# sysctl register map
Vendor: Texas Instruments
Peripheral module from a debugger description file (folder tm4e123gh6zrb).
Registers are 32-bit, read-write, no defined reset value unless marked. A register's access mark holds for its fields unless they carry their own. Offsets are as the file gives them; lines under a group give offsets from that group; [hi:lo] are bit positions; {n}, {i} and the like mark numbered series; 'fields as' and 'values as' point back to an identical list; <NAME> marks a mode.

## SYSCTL — System Control register addresses
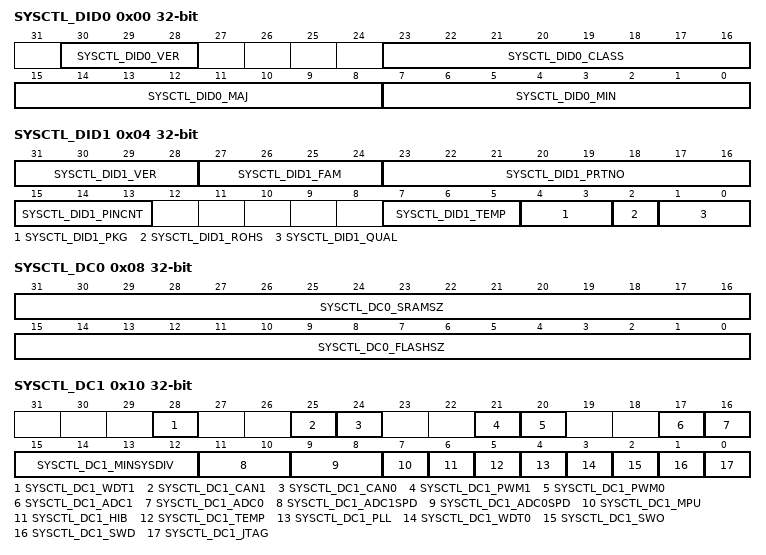
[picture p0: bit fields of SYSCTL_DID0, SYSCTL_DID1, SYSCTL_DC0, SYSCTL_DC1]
0x00 SYSCTL_DID0 ro — Device Identification 0
  [30:28] SYSCTL_DID0_VER — DID0 Version
    1=Second version of the DID0 register format
  [23:16] SYSCTL_DID0_CLASS — Device Class
    5=SYSCTL_DID0_CLASS_TM4C123 (Tiva TM4C123x and TM4E123x microcontrollers)
  [15:8] SYSCTL_DID0_MAJ — Major Revision
    0=SYSCTL_DID0_MAJ_REVA (Revision A (initial device)); 1=SYSCTL_DID0_MAJ_REVB (Revision B (first base layer revision)); 2=SYSCTL_DID0_MAJ_REVC (Revision C (second base layer revision))
  [7:0] SYSCTL_DID0_MIN — Minor Revision
    0=Initial device, or a major revision update; 1=First metal layer change; 2=Second metal layer change
0x04 SYSCTL_DID1 ro — Device Identification 1
  [31:28] SYSCTL_DID1_VER — DID1 Version
  [27:24] SYSCTL_DID1_FAM — Family
  [23:16] SYSCTL_DID1_PRTNO — Part Number
  [15:13] SYSCTL_DID1_PINCNT — Package Pin Count
    2=100-pin LQFP package; 3=64-pin LQFP package; 4=144-pin LQFP package; 5=157-pin BGA package; 6=128-pin TQFP package
  [7:5] SYSCTL_DID1_TEMP — Temperature Range
    1=SYSCTL_DID1_TEMP_I (Industrial temperature range); 2=SYSCTL_DID1_TEMP_E (Extended temperature range); 3=SYSCTL_DID1_TEMP_IE (Available in both industrial temperature range (-40C to 85C) and extended temperature range (-40C to 105C) devices. See)
  [4:3] SYSCTL_DID1_PKG — Package Type
    1=SYSCTL_DID1_PKG_QFP (QFP package); 2=SYSCTL_DID1_PKG_BGA (BGA package)
  [2] SYSCTL_DID1_ROHS — RoHS-Compliance
  [1:0] SYSCTL_DID1_QUAL — Qualification Status
    0=SYSCTL_DID1_QUAL_ES (Engineering Sample (unqualified)); 1=SYSCTL_DID1_QUAL_PP (Pilot Production (unqualified)); 2=SYSCTL_DID1_QUAL_FQ (Fully Qualified)
0x08 SYSCTL_DC0 ro — Device Capabilities 0
  [31:16] SYSCTL_DC0_SRAMSZ — SRAM Size
    7=SYSCTL_DC0_SRAMSZ_2KB (2 KB of SRAM); 15=SYSCTL_DC0_SRAMSZ_4KB (4 KB of SRAM); 23=SYSCTL_DC0_SRAMSZ_6KB (6 KB of SRAM); 31=SYSCTL_DC0_SRAMSZ_8KB (8 KB of SRAM); 47=SYSCTL_DC0_SRAMSZ_12KB (12 KB of SRAM); 63=SYSCTL_DC0_SRAMSZ_16KB (16 KB of SRAM); 79=SYSCTL_DC0_SRAMSZ_20KB (20 KB of SRAM); 95=SYSCTL_DC0_SRAMSZ_24KB (24 KB of SRAM); 127=SYSCTL_DC0_SRAMSZ_32KB (32 KB of SRAM)
  [15:0] SYSCTL_DC0_FLASHSZ — Flash Size
    3=SYSCTL_DC0_FLASHSZ_8KB (8 KB of Flash); 7=SYSCTL_DC0_FLASHSZ_16KB (16 KB of Flash); 15=SYSCTL_DC0_FLASHSZ_32KB (32 KB of Flash); 31=SYSCTL_DC0_FLASHSZ_64KB (64 KB of Flash); 47=SYSCTL_DC0_FLASHSZ_96KB (96 KB of Flash); 63=SYSCTL_DC0_FLASHSZ_128K (128 KB of Flash); 95=SYSCTL_DC0_FLASHSZ_192K (192 KB of Flash); 127=SYSCTL_DC0_FLASHSZ_256K (256 KB of Flash)
0x10 SYSCTL_DC1 ro — Device Capabilities 1
  [28] SYSCTL_DC1_WDT1 — Watchdog Timer1 Present
  [25] SYSCTL_DC1_CAN1 — CAN Module 1 Present
  [24] SYSCTL_DC1_CAN0 — CAN Module 0 Present
  [21] SYSCTL_DC1_PWM1 — PWM Module 1 Present
  [20] SYSCTL_DC1_PWM0 — PWM Module 0 Present
  [17] SYSCTL_DC1_ADC1 — ADC Module 1 Present
  [16] SYSCTL_DC1_ADC0 — ADC Module 0 Present
  [15:12] SYSCTL_DC1_MINSYSDIV — System Clock Divider
    2=Specifies an 80-MHz CPU clock with a PLL divider of 2.5; 3=Specifies a 50-MHz CPU clock with a PLL divider of 4; 4=Specifies a 40-MHz CPU clock with a PLL divider of 5; 7=Specifies a 25-MHz clock with a PLL divider of 8; 9=Specifies a 20-MHz clock with a PLL divider of 10
  [11:10] SYSCTL_DC1_ADC1SPD — Max ADC1 Speed
    0=SYSCTL_DC1_ADC1SPD_125K (125K samples/second); 1=SYSCTL_DC1_ADC1SPD_250K (250K samples/second); 2=SYSCTL_DC1_ADC1SPD_500K (500K samples/second); 3=SYSCTL_DC1_ADC1SPD_1M (1M samples/second)
  [9:8] SYSCTL_DC1_ADC0SPD — Max ADC0 Speed
    0=SYSCTL_DC1_ADC0SPD_125K (125K samples/second); 1=SYSCTL_DC1_ADC0SPD_250K (250K samples/second); 2=SYSCTL_DC1_ADC0SPD_500K (500K samples/second); 3=SYSCTL_DC1_ADC0SPD_1M (1M samples/second)
  [7] SYSCTL_DC1_MPU — MPU Present
  [6] SYSCTL_DC1_HIB — Hibernation Module Present
  [5] SYSCTL_DC1_TEMP — Temp Sensor Present
  [4] SYSCTL_DC1_PLL — PLL Present
  [3] SYSCTL_DC1_WDT0 — Watchdog Timer 0 Present
  [2] SYSCTL_DC1_SWO — SWO Trace Port Present
  [1] SYSCTL_DC1_SWD — SWD Present
  [0] SYSCTL_DC1_JTAG — JTAG Present
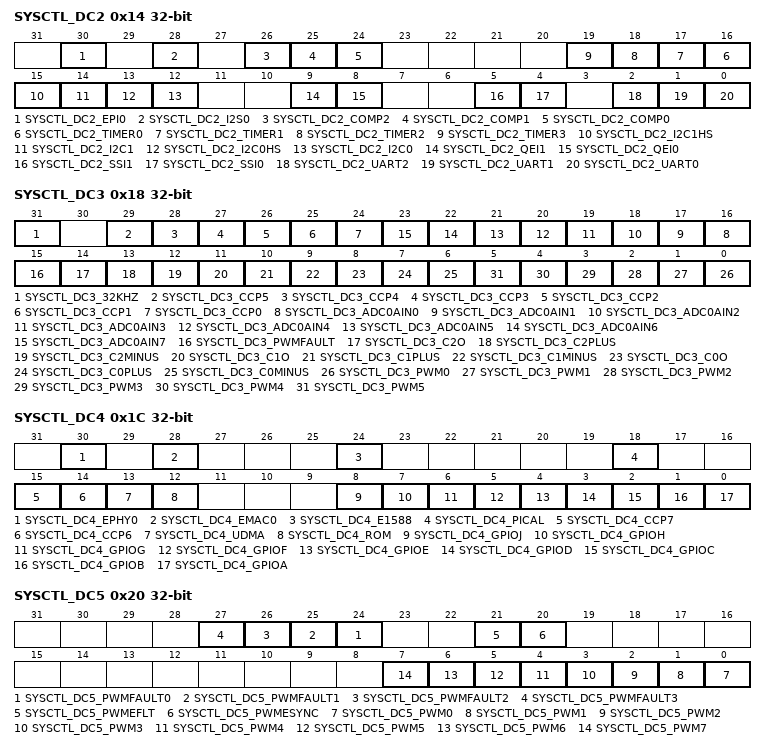
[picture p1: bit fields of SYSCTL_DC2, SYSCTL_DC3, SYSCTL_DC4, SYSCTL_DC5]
0x14 SYSCTL_DC2 ro — Device Capabilities 2
  [30] SYSCTL_DC2_EPI0 — EPI Module 0 Present
  [28] SYSCTL_DC2_I2S0 — I2S Module 0 Present
  [26] SYSCTL_DC2_COMP2 — Analog Comparator 2 Present
  [25] SYSCTL_DC2_COMP1 — Analog Comparator 1 Present
  [24] SYSCTL_DC2_COMP0 — Analog Comparator 0 Present
  [n+16] SYSCTL_DC2_TIMER{n} (n=0..3) — Timer Module {n} Present
  [15] SYSCTL_DC2_I2C1HS — I2C Module 1 Speed
  [14] SYSCTL_DC2_I2C1 — I2C Module 1 Present
  [13] SYSCTL_DC2_I2C0HS — I2C Module 0 Speed
  [12] SYSCTL_DC2_I2C0 — I2C Module 0 Present
  [9] SYSCTL_DC2_QEI1 — QEI Module 1 Present
  [8] SYSCTL_DC2_QEI0 — QEI Module 0 Present
  [5] SYSCTL_DC2_SSI1 — SSI Module 1 Present
  [4] SYSCTL_DC2_SSI0 — SSI Module 0 Present
  [2] SYSCTL_DC2_UART2 — UART Module 2 Present
  [1] SYSCTL_DC2_UART1 — UART Module 1 Present
  [0] SYSCTL_DC2_UART0 — UART Module 0 Present
0x18 SYSCTL_DC3 ro — Device Capabilities 3
  [31] SYSCTL_DC3_32KHZ — 32KHz Input Clock Available
  [29] SYSCTL_DC3_CCP5 — T2CCP1 Pin Present
  [28] SYSCTL_DC3_CCP4 — T2CCP0 Pin Present
  [27] SYSCTL_DC3_CCP3 — T1CCP1 Pin Present
  [26] SYSCTL_DC3_CCP2 — T1CCP0 Pin Present
  [25] SYSCTL_DC3_CCP1 — T0CCP1 Pin Present
  [24] SYSCTL_DC3_CCP0 — T0CCP0 Pin Present
  [n+16] SYSCTL_DC3_ADC0AIN{n} (n=0..7) — ADC Module 0 AIN{n} Pin Present
  [15] SYSCTL_DC3_PWMFAULT — PWM Fault Pin Present
  [14] SYSCTL_DC3_C2O — C2o Pin Present
  [13] SYSCTL_DC3_C2PLUS — C2+ Pin Present
  [12] SYSCTL_DC3_C2MINUS — C2- Pin Present
  [11] SYSCTL_DC3_C1O — C1o Pin Present
  [10] SYSCTL_DC3_C1PLUS — C1+ Pin Present
  [9] SYSCTL_DC3_C1MINUS — C1- Pin Present
  [8] SYSCTL_DC3_C0O — C0o Pin Present
  [7] SYSCTL_DC3_C0PLUS — C0+ Pin Present
  [6] SYSCTL_DC3_C0MINUS — C0- Pin Present
  [n] SYSCTL_DC3_PWM{n} (n=0..5) — PWM{n} Pin Present
0x1C SYSCTL_DC4 ro — Device Capabilities 4
  [30] SYSCTL_DC4_EPHY0 — Ethernet PHY Layer 0 Present
  [28] SYSCTL_DC4_EMAC0 — Ethernet MAC Layer 0 Present
  [24] SYSCTL_DC4_E1588 — 1588 Capable
  [18] SYSCTL_DC4_PICAL — PIOSC Calibrate
  [15] SYSCTL_DC4_CCP7 — T3CCP1 Pin Present
  [14] SYSCTL_DC4_CCP6 — T3CCP0 Pin Present
  [13] SYSCTL_DC4_UDMA — Micro-DMA Module Present
  [12] SYSCTL_DC4_ROM — Internal Code ROM Present
  [8] SYSCTL_DC4_GPIOJ — GPIO Port J Present
  [7] SYSCTL_DC4_GPIOH — GPIO Port H Present
  [6] SYSCTL_DC4_GPIOG — GPIO Port G Present
  [5] SYSCTL_DC4_GPIOF — GPIO Port F Present
  [4] SYSCTL_DC4_GPIOE — GPIO Port E Present
  [3] SYSCTL_DC4_GPIOD — GPIO Port D Present
  [2] SYSCTL_DC4_GPIOC — GPIO Port C Present
  [1] SYSCTL_DC4_GPIOB — GPIO Port B Present
  [0] SYSCTL_DC4_GPIOA — GPIO Port A Present
0x20 SYSCTL_DC5 ro — Device Capabilities 5
  [n+24] SYSCTL_DC5_PWMFAULT{n} (n=0..3) — PWM Fault {n} Pin Present
  [21] SYSCTL_DC5_PWMEFLT — PWM Extended Fault Active
  [20] SYSCTL_DC5_PWMESYNC — PWM Extended SYNC Active
  [n] SYSCTL_DC5_PWM{n} (n=0..7) — PWM{n} Pin Present
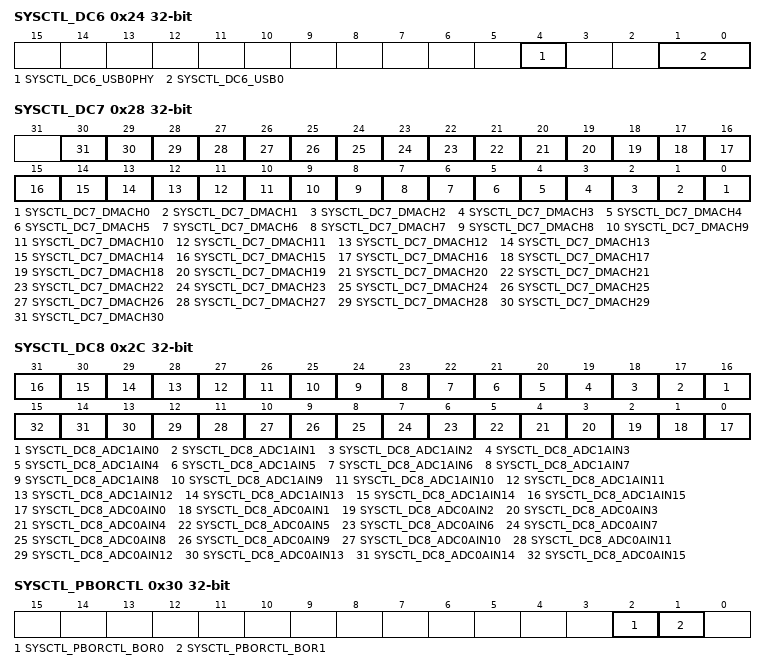
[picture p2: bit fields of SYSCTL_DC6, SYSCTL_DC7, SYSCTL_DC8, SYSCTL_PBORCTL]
0x24 SYSCTL_DC6 ro — Device Capabilities 6
  [4] SYSCTL_DC6_USB0PHY — USB Module 0 PHY Present
  [1:0] SYSCTL_DC6_USB0 — USB Module 0 Present
    1=SYSCTL_DC6_USB0_DEV (USB0 is Device Only); 2=SYSCTL_DC6_USB0_HOSTDEV (USB is Device or Host); 3=SYSCTL_DC6_USB0_OTG (USB0 is OTG)
0x28 SYSCTL_DC7 ro — Device Capabilities 7
  [n] SYSCTL_DC7_DMACH{n} (n=0..30) — DMA Channel {n}
0x2C SYSCTL_DC8 ro — Device Capabilities 8
  [n+16] SYSCTL_DC8_ADC1AIN{n} (n=0..15) — ADC Module 1 AIN{n} Pin Present
  [n] SYSCTL_DC8_ADC0AIN{n} (n=0..15) — ADC Module 0 AIN{n} Pin Present
0x30 SYSCTL_PBORCTL — Brown-Out Reset Control
  [2] SYSCTL_PBORCTL_BOR0 — VDD under BOR0 Event Action
  [1] SYSCTL_PBORCTL_BOR1 — VDD under BOR1 Event Action
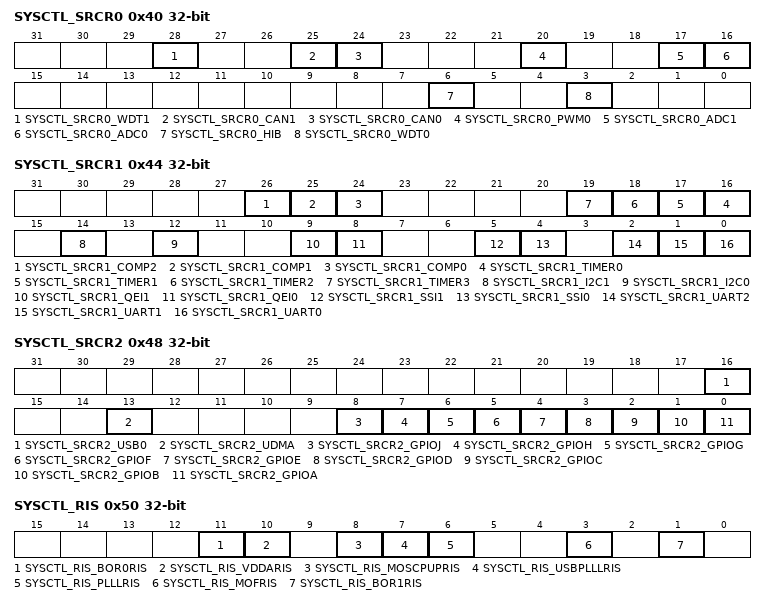
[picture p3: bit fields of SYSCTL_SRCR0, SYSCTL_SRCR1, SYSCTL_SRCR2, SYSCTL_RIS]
0x40 SYSCTL_SRCR0 ro — Software Reset Control 0
  [28] SYSCTL_SRCR0_WDT1 — WDT1 Reset Control
  [25] SYSCTL_SRCR0_CAN1 — CAN1 Reset Control
  [24] SYSCTL_SRCR0_CAN0 — CAN0 Reset Control
  [20] SYSCTL_SRCR0_PWM0 — PWM Reset Control
  [17] SYSCTL_SRCR0_ADC1 — ADC1 Reset Control
  [16] SYSCTL_SRCR0_ADC0 — ADC0 Reset Control
  [6] SYSCTL_SRCR0_HIB — HIB Reset Control
  [3] SYSCTL_SRCR0_WDT0 — WDT0 Reset Control
0x44 SYSCTL_SRCR1 ro — Software Reset Control 1
  [26] SYSCTL_SRCR1_COMP2 — Analog Comp 2 Reset Control
  [25] SYSCTL_SRCR1_COMP1 — Analog Comp 1 Reset Control
  [24] SYSCTL_SRCR1_COMP0 — Analog Comp 0 Reset Control
  [n+16] SYSCTL_SRCR1_TIMER{n} (n=0..3) — Timer {n} Reset Control
  [14] SYSCTL_SRCR1_I2C1 — I2C1 Reset Control
  [12] SYSCTL_SRCR1_I2C0 — I2C0 Reset Control
  [9] SYSCTL_SRCR1_QEI1 — QEI1 Reset Control
  [8] SYSCTL_SRCR1_QEI0 — QEI0 Reset Control
  [5] SYSCTL_SRCR1_SSI1 — SSI1 Reset Control
  [4] SYSCTL_SRCR1_SSI0 — SSI0 Reset Control
  [2] SYSCTL_SRCR1_UART2 — UART2 Reset Control
  [1] SYSCTL_SRCR1_UART1 — UART1 Reset Control
  [0] SYSCTL_SRCR1_UART0 — UART0 Reset Control
0x48 SYSCTL_SRCR2 ro — Software Reset Control 2
  [16] SYSCTL_SRCR2_USB0 — USB0 Reset Control
  [13] SYSCTL_SRCR2_UDMA — Micro-DMA Reset Control
  [8] SYSCTL_SRCR2_GPIOJ — Port J Reset Control
  [7] SYSCTL_SRCR2_GPIOH — Port H Reset Control
  [6] SYSCTL_SRCR2_GPIOG — Port G Reset Control
  [5] SYSCTL_SRCR2_GPIOF — Port F Reset Control
  [4] SYSCTL_SRCR2_GPIOE — Port E Reset Control
  [3] SYSCTL_SRCR2_GPIOD — Port D Reset Control
  [2] SYSCTL_SRCR2_GPIOC — Port C Reset Control
  [1] SYSCTL_SRCR2_GPIOB — Port B Reset Control
  [0] SYSCTL_SRCR2_GPIOA — Port A Reset Control
0x50 SYSCTL_RIS ro — Raw Interrupt Status
  [11] SYSCTL_RIS_BOR0RIS — VDD under BOR0 Raw Interrupt Status
  [10] SYSCTL_RIS_VDDARIS — VDDA Power OK Event Raw Interrupt Status
  [8] SYSCTL_RIS_MOSCPUPRIS — MOSC Power Up Raw Interrupt Status
  [7] SYSCTL_RIS_USBPLLLRIS — USB PLL Lock Raw Interrupt Status
  [6] SYSCTL_RIS_PLLLRIS — PLL Lock Raw Interrupt Status
  [3] SYSCTL_RIS_MOFRIS — Main Oscillator Failure Raw Interrupt Status
  [1] SYSCTL_RIS_BOR1RIS — VDD under BOR1 Raw Interrupt Status
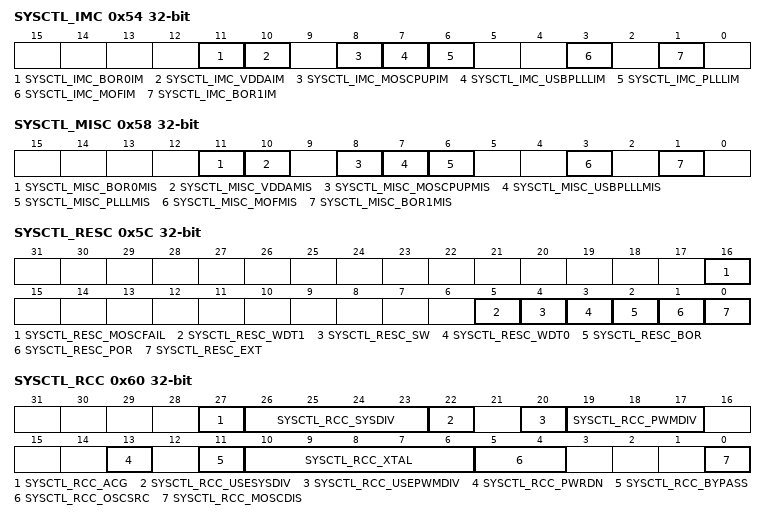
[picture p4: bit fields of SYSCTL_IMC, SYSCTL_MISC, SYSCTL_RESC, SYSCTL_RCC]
0x54 SYSCTL_IMC — Interrupt Mask Control
  [11] SYSCTL_IMC_BOR0IM — VDD under BOR0 Interrupt Mask
  [10] SYSCTL_IMC_VDDAIM — VDDA Power OK Interrupt Mask
  [8] SYSCTL_IMC_MOSCPUPIM — MOSC Power Up Interrupt Mask
  [7] SYSCTL_IMC_USBPLLLIM — USB PLL Lock Interrupt Mask
  [6] SYSCTL_IMC_PLLLIM — PLL Lock Interrupt Mask
  [3] SYSCTL_IMC_MOFIM — Main Oscillator Failure Interrupt Mask
  [1] SYSCTL_IMC_BOR1IM — VDD under BOR1 Interrupt Mask
0x58 SYSCTL_MISC — Masked Interrupt Status and Clear
  [11] SYSCTL_MISC_BOR0MIS — VDD under BOR0 Masked Interrupt Status
  [10] SYSCTL_MISC_VDDAMIS — VDDA Power OK Masked Interrupt Status
  [8] SYSCTL_MISC_MOSCPUPMIS — MOSC Power Up Masked Interrupt Status
  [7] SYSCTL_MISC_USBPLLLMIS — USB PLL Lock Masked Interrupt Status
  [6] SYSCTL_MISC_PLLLMIS — PLL Lock Masked Interrupt Status
  [3] SYSCTL_MISC_MOFMIS — Main Oscillator Failure Masked Interrupt Status
  [1] SYSCTL_MISC_BOR1MIS — VDD under BOR1 Masked Interrupt Status
0x5C SYSCTL_RESC — Reset Cause
  [16] SYSCTL_RESC_MOSCFAIL — MOSC Failure Reset
  [5] SYSCTL_RESC_WDT1 — Watchdog Timer 1 Reset
  [4] SYSCTL_RESC_SW — Software Reset
  [3] SYSCTL_RESC_WDT0 — Watchdog Timer 0 Reset
  [2] SYSCTL_RESC_BOR — Brown-Out Reset
  [1] SYSCTL_RESC_POR — Power-On Reset
  [0] SYSCTL_RESC_EXT — External Reset
0x60 SYSCTL_RCC — Run-Mode Clock Configuration
  [27] SYSCTL_RCC_ACG — Auto Clock Gating
  [26:23] SYSCTL_RCC_SYSDIV — System Clock Divisor
  [22] SYSCTL_RCC_USESYSDIV — Enable System Clock Divider
  [20] SYSCTL_RCC_USEPWMDIV — Enable PWM Clock Divisor
  [19:17] SYSCTL_RCC_PWMDIV — PWM Unit Clock Divisor
    0=PWM clock /2; 1=PWM clock /4; 2=PWM clock /8; 3=PWM clock /16; 4=PWM clock /32; 5=PWM clock /64
  [13] SYSCTL_RCC_PWRDN — PLL Power Down
  [11] SYSCTL_RCC_BYPASS — PLL Bypass
  [10:6] SYSCTL_RCC_XTAL — Crystal Value
    6=SYSCTL_RCC_XTAL_4MHZ (4 MHz); 7=SYSCTL_RCC_XTAL_4_09MHZ (4.096 MHz); 8=SYSCTL_RCC_XTAL_4_91MHZ (4.9152 MHz); 9=SYSCTL_RCC_XTAL_5MHZ (5 MHz); 10=SYSCTL_RCC_XTAL_5_12MHZ (5.12 MHz); 11=SYSCTL_RCC_XTAL_6MHZ (6 MHz); 12=SYSCTL_RCC_XTAL_6_14MHZ (6.144 MHz); 13=SYSCTL_RCC_XTAL_7_37MHZ (7.3728 MHz); 14=SYSCTL_RCC_XTAL_8MHZ (8 MHz); 15=SYSCTL_RCC_XTAL_8_19MHZ (8.192 MHz); 16=SYSCTL_RCC_XTAL_10MHZ (10 MHz); 17=SYSCTL_RCC_XTAL_12MHZ (12 MHz); 18=SYSCTL_RCC_XTAL_12_2MHZ (12.288 MHz); 19=SYSCTL_RCC_XTAL_13_5MHZ (13.56 MHz); 20=SYSCTL_RCC_XTAL_14_3MHZ (14.31818 MHz); 21=SYSCTL_RCC_XTAL_16MHZ (16 MHz); 22=SYSCTL_RCC_XTAL_16_3MHZ (16.384 MHz); 23=SYSCTL_RCC_XTAL_18MHZ (18.0 MHz (USB)); 24=SYSCTL_RCC_XTAL_20MHZ (20.0 MHz (USB)); 25=SYSCTL_RCC_XTAL_24MHZ (24.0 MHz (USB)); 26=SYSCTL_RCC_XTAL_25MHZ (25.0 MHz (USB))
  [5:4] SYSCTL_RCC_OSCSRC — Oscillator Source
    0=SYSCTL_RCC_OSCSRC_MAIN (MOSC); 1=SYSCTL_RCC_OSCSRC_INT (IOSC); 2=SYSCTL_RCC_OSCSRC_INT4 (IOSC/4); 3=LFIOSC
  [0] SYSCTL_RCC_MOSCDIS — Main Oscillator Disable
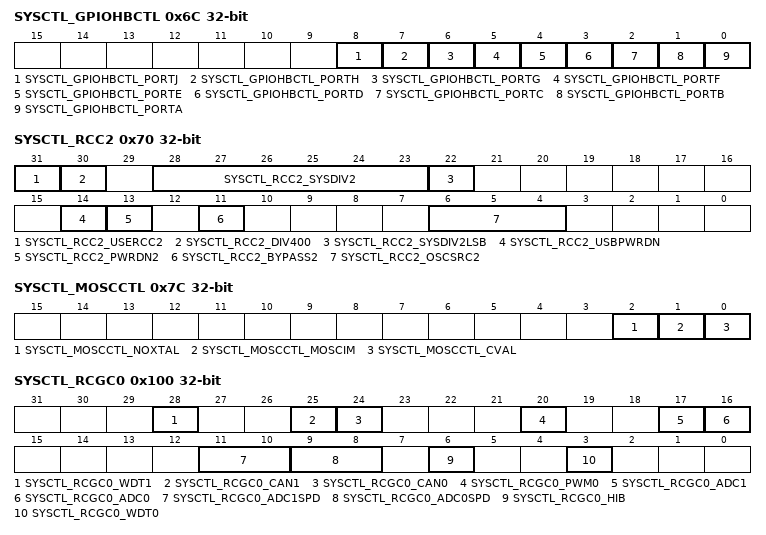
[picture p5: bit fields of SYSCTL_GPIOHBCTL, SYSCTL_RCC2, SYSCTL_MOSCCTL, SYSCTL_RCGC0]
0x6C SYSCTL_GPIOHBCTL — GPIO High-Performance Bus Control
  [8] SYSCTL_GPIOHBCTL_PORTJ — Port J Advanced High-Performance Bus
  [7] SYSCTL_GPIOHBCTL_PORTH — Port H Advanced High-Performance Bus
  [6] SYSCTL_GPIOHBCTL_PORTG — Port G Advanced High-Performance Bus
  [5] SYSCTL_GPIOHBCTL_PORTF — Port F Advanced High-Performance Bus
  [4] SYSCTL_GPIOHBCTL_PORTE — Port E Advanced High-Performance Bus
  [3] SYSCTL_GPIOHBCTL_PORTD — Port D Advanced High-Performance Bus
  [2] SYSCTL_GPIOHBCTL_PORTC — Port C Advanced High-Performance Bus
  [1] SYSCTL_GPIOHBCTL_PORTB — Port B Advanced High-Performance Bus
  [0] SYSCTL_GPIOHBCTL_PORTA — Port A Advanced High-Performance Bus
0x70 SYSCTL_RCC2 — Run-Mode Clock Configuration 2
  [31] SYSCTL_RCC2_USERCC2 — Use RCC2
  [30] SYSCTL_RCC2_DIV400 — Divide PLL as 400 MHz vs. 200 MHz
  [28:23] SYSCTL_RCC2_SYSDIV2 — System Clock Divisor 2
  [22] SYSCTL_RCC2_SYSDIV2LSB — Additional LSB for SYSDIV2
  [14] SYSCTL_RCC2_USBPWRDN — Power-Down USB PLL
  [13] SYSCTL_RCC2_PWRDN2 — Power-Down PLL 2
  [11] SYSCTL_RCC2_BYPASS2 — PLL Bypass 2
  [6:4] SYSCTL_RCC2_OSCSRC2 — Oscillator Source 2
    0=SYSCTL_RCC2_OSCSRC2_MO (MOSC); 1=SYSCTL_RCC2_OSCSRC2_IO (PIOSC); 2=SYSCTL_RCC2_OSCSRC2_IO4 (PIOSC/4); 3=LFIOSC; 7=32.768 kHz
0x7C SYSCTL_MOSCCTL — Main Oscillator Control
  [2] SYSCTL_MOSCCTL_NOXTAL — No Crystal Connected
  [1] SYSCTL_MOSCCTL_MOSCIM — MOSC Failure Action
  [0] SYSCTL_MOSCCTL_CVAL — Clock Validation for MOSC
0x100 SYSCTL_RCGC0 ro — Run Mode Clock Gating Control Register 0
  [28] SYSCTL_RCGC0_WDT1 — WDT1 Clock Gating Control
  [25] SYSCTL_RCGC0_CAN1 — CAN1 Clock Gating Control
  [24] SYSCTL_RCGC0_CAN0 — CAN0 Clock Gating Control
  [20] SYSCTL_RCGC0_PWM0 — PWM Clock Gating Control
  [17] SYSCTL_RCGC0_ADC1 — ADC1 Clock Gating Control
  [16] SYSCTL_RCGC0_ADC0 — ADC0 Clock Gating Control
  [11:10] SYSCTL_RCGC0_ADC1SPD — ADC1 Sample Speed
    0=SYSCTL_RCGC0_ADC1SPD_125K (125K samples/second); 1=SYSCTL_RCGC0_ADC1SPD_250K (250K samples/second); 2=SYSCTL_RCGC0_ADC1SPD_500K (500K samples/second); 3=SYSCTL_RCGC0_ADC1SPD_1M (1M samples/second)
  [9:8] SYSCTL_RCGC0_ADC0SPD — ADC0 Sample Speed
    0=SYSCTL_RCGC0_ADC0SPD_125K (125K samples/second); 1=SYSCTL_RCGC0_ADC0SPD_250K (250K samples/second); 2=SYSCTL_RCGC0_ADC0SPD_500K (500K samples/second); 3=SYSCTL_RCGC0_ADC0SPD_1M (1M samples/second)
  [6] SYSCTL_RCGC0_HIB — HIB Clock Gating Control
  [3] SYSCTL_RCGC0_WDT0 — WDT0 Clock Gating Control
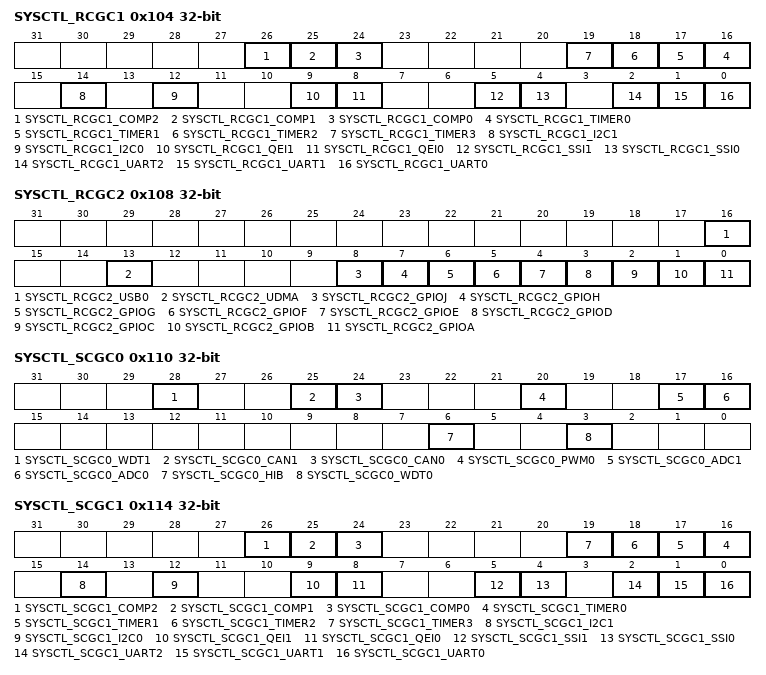
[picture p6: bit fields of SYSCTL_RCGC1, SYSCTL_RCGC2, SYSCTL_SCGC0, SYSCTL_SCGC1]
0x104 SYSCTL_RCGC1 ro — Run Mode Clock Gating Control Register 1
  [26] SYSCTL_RCGC1_COMP2 — Analog Comparator 2 Clock Gating
  [25] SYSCTL_RCGC1_COMP1 — Analog Comparator 1 Clock Gating
  [24] SYSCTL_RCGC1_COMP0 — Analog Comparator 0 Clock Gating
  [n+16] SYSCTL_RCGC1_TIMER{n} (n=0..3) — Timer {n} Clock Gating Control
  [14] SYSCTL_RCGC1_I2C1 — I2C1 Clock Gating Control
  [12] SYSCTL_RCGC1_I2C0 — I2C0 Clock Gating Control
  [9] SYSCTL_RCGC1_QEI1 — QEI1 Clock Gating Control
  [8] SYSCTL_RCGC1_QEI0 — QEI0 Clock Gating Control
  [5] SYSCTL_RCGC1_SSI1 — SSI1 Clock Gating Control
  [4] SYSCTL_RCGC1_SSI0 — SSI0 Clock Gating Control
  [2] SYSCTL_RCGC1_UART2 — UART2 Clock Gating Control
  [1] SYSCTL_RCGC1_UART1 — UART1 Clock Gating Control
  [0] SYSCTL_RCGC1_UART0 — UART0 Clock Gating Control
0x108 SYSCTL_RCGC2 ro — Run Mode Clock Gating Control Register 2
  [16] SYSCTL_RCGC2_USB0 — USB0 Clock Gating Control
  [13] SYSCTL_RCGC2_UDMA — Micro-DMA Clock Gating Control
  [8] SYSCTL_RCGC2_GPIOJ — Port J Clock Gating Control
  [7] SYSCTL_RCGC2_GPIOH — Port H Clock Gating Control
  [6] SYSCTL_RCGC2_GPIOG — Port G Clock Gating Control
  [5] SYSCTL_RCGC2_GPIOF — Port F Clock Gating Control
  [4] SYSCTL_RCGC2_GPIOE — Port E Clock Gating Control
  [3] SYSCTL_RCGC2_GPIOD — Port D Clock Gating Control
  [2] SYSCTL_RCGC2_GPIOC — Port C Clock Gating Control
  [1] SYSCTL_RCGC2_GPIOB — Port B Clock Gating Control
  [0] SYSCTL_RCGC2_GPIOA — Port A Clock Gating Control
0x110 SYSCTL_SCGC0 ro — Sleep Mode Clock Gating Control Register 0
  [28] SYSCTL_SCGC0_WDT1 — WDT1 Clock Gating Control
  [25] SYSCTL_SCGC0_CAN1 — CAN1 Clock Gating Control
  [24] SYSCTL_SCGC0_CAN0 — CAN0 Clock Gating Control
  [20] SYSCTL_SCGC0_PWM0 — PWM Clock Gating Control
  [17] SYSCTL_SCGC0_ADC1 — ADC1 Clock Gating Control
  [16] SYSCTL_SCGC0_ADC0 — ADC0 Clock Gating Control
  [6] SYSCTL_SCGC0_HIB — HIB Clock Gating Control
  [3] SYSCTL_SCGC0_WDT0 — WDT0 Clock Gating Control
0x114 SYSCTL_SCGC1 ro — Sleep Mode Clock Gating Control Register 1
  [26] SYSCTL_SCGC1_COMP2 — Analog Comparator 2 Clock Gating
  [25] SYSCTL_SCGC1_COMP1 — Analog Comparator 1 Clock Gating
  [24] SYSCTL_SCGC1_COMP0 — Analog Comparator 0 Clock Gating
  [n+16] SYSCTL_SCGC1_TIMER{n} (n=0..3) — Timer {n} Clock Gating Control
  [14] SYSCTL_SCGC1_I2C1 — I2C1 Clock Gating Control
  [12] SYSCTL_SCGC1_I2C0 — I2C0 Clock Gating Control
  [9] SYSCTL_SCGC1_QEI1 — QEI1 Clock Gating Control
  [8] SYSCTL_SCGC1_QEI0 — QEI0 Clock Gating Control
  [5] SYSCTL_SCGC1_SSI1 — SSI1 Clock Gating Control
  [4] SYSCTL_SCGC1_SSI0 — SSI0 Clock Gating Control
  [2] SYSCTL_SCGC1_UART2 — UART2 Clock Gating Control
  [1] SYSCTL_SCGC1_UART1 — UART1 Clock Gating Control
  [0] SYSCTL_SCGC1_UART0 — UART0 Clock Gating Control
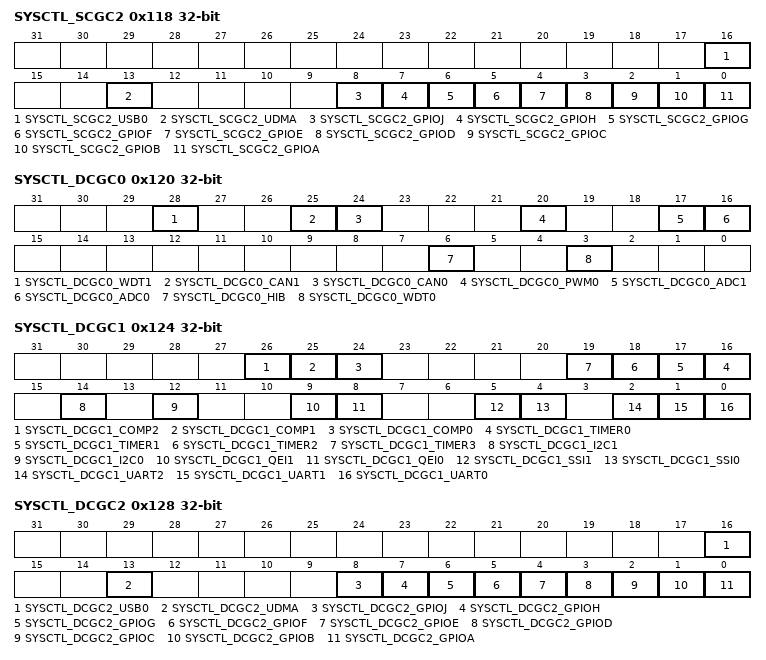
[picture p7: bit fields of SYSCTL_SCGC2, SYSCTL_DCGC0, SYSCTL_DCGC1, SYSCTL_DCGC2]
0x118 SYSCTL_SCGC2 ro — Sleep Mode Clock Gating Control Register 2
  [16] SYSCTL_SCGC2_USB0 — USB0 Clock Gating Control
  [13] SYSCTL_SCGC2_UDMA — Micro-DMA Clock Gating Control
  [8] SYSCTL_SCGC2_GPIOJ — Port J Clock Gating Control
  [7] SYSCTL_SCGC2_GPIOH — Port H Clock Gating Control
  [6] SYSCTL_SCGC2_GPIOG — Port G Clock Gating Control
  [5] SYSCTL_SCGC2_GPIOF — Port F Clock Gating Control
  [4] SYSCTL_SCGC2_GPIOE — Port E Clock Gating Control
  [3] SYSCTL_SCGC2_GPIOD — Port D Clock Gating Control
  [2] SYSCTL_SCGC2_GPIOC — Port C Clock Gating Control
  [1] SYSCTL_SCGC2_GPIOB — Port B Clock Gating Control
  [0] SYSCTL_SCGC2_GPIOA — Port A Clock Gating Control
0x120 SYSCTL_DCGC0 ro — Deep Sleep Mode Clock Gating Control Register 0
  [28] SYSCTL_DCGC0_WDT1 — WDT1 Clock Gating Control
  [25] SYSCTL_DCGC0_CAN1 — CAN1 Clock Gating Control
  [24] SYSCTL_DCGC0_CAN0 — CAN0 Clock Gating Control
  [20] SYSCTL_DCGC0_PWM0 — PWM Clock Gating Control
  [17] SYSCTL_DCGC0_ADC1 — ADC1 Clock Gating Control
  [16] SYSCTL_DCGC0_ADC0 — ADC0 Clock Gating Control
  [6] SYSCTL_DCGC0_HIB — HIB Clock Gating Control
  [3] SYSCTL_DCGC0_WDT0 — WDT0 Clock Gating Control
0x124 SYSCTL_DCGC1 ro — Deep-Sleep Mode Clock Gating Control Register 1
  [26] SYSCTL_DCGC1_COMP2 — Analog Comparator 2 Clock Gating
  [25] SYSCTL_DCGC1_COMP1 — Analog Comparator 1 Clock Gating
  [24] SYSCTL_DCGC1_COMP0 — Analog Comparator 0 Clock Gating
  [n+16] SYSCTL_DCGC1_TIMER{n} (n=0..3) — Timer {n} Clock Gating Control
  [14] SYSCTL_DCGC1_I2C1 — I2C1 Clock Gating Control
  [12] SYSCTL_DCGC1_I2C0 — I2C0 Clock Gating Control
  [9] SYSCTL_DCGC1_QEI1 — QEI1 Clock Gating Control
  [8] SYSCTL_DCGC1_QEI0 — QEI0 Clock Gating Control
  [5] SYSCTL_DCGC1_SSI1 — SSI1 Clock Gating Control
  [4] SYSCTL_DCGC1_SSI0 — SSI0 Clock Gating Control
  [2] SYSCTL_DCGC1_UART2 — UART2 Clock Gating Control
  [1] SYSCTL_DCGC1_UART1 — UART1 Clock Gating Control
  [0] SYSCTL_DCGC1_UART0 — UART0 Clock Gating Control
0x128 SYSCTL_DCGC2 ro — Deep Sleep Mode Clock Gating Control Register 2
  [16] SYSCTL_DCGC2_USB0 — USB0 Clock Gating Control
  [13] SYSCTL_DCGC2_UDMA — Micro-DMA Clock Gating Control
  [8] SYSCTL_DCGC2_GPIOJ — Port J Clock Gating Control
  [7] SYSCTL_DCGC2_GPIOH — Port H Clock Gating Control
  [6] SYSCTL_DCGC2_GPIOG — Port G Clock Gating Control
  [5] SYSCTL_DCGC2_GPIOF — Port F Clock Gating Control
  [4] SYSCTL_DCGC2_GPIOE — Port E Clock Gating Control
  [3] SYSCTL_DCGC2_GPIOD — Port D Clock Gating Control
  [2] SYSCTL_DCGC2_GPIOC — Port C Clock Gating Control
  [1] SYSCTL_DCGC2_GPIOB — Port B Clock Gating Control
  [0] SYSCTL_DCGC2_GPIOA — Port A Clock Gating Control
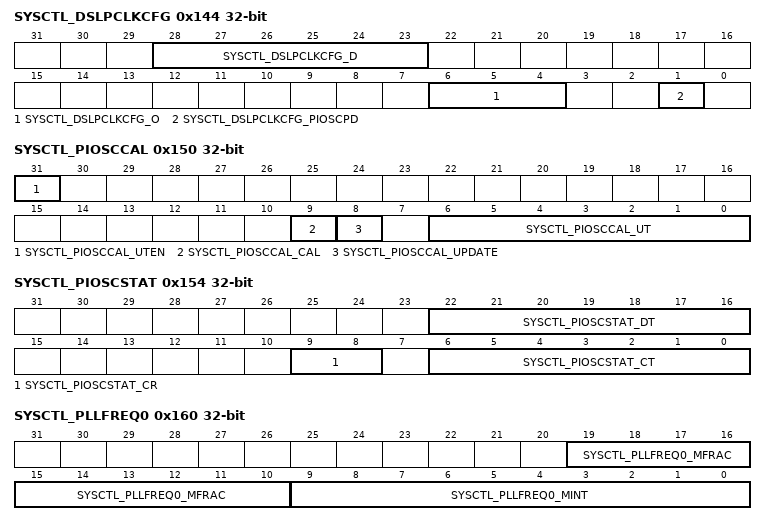
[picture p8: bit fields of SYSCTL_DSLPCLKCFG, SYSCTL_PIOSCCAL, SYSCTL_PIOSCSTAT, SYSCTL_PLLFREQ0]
0x144 SYSCTL_DSLPCLKCFG — Deep Sleep Clock Configuration
  [28:23] SYSCTL_DSLPCLKCFG_D — Divider Field Override
  [6:4] SYSCTL_DSLPCLKCFG_O — Clock Source
    0=SYSCTL_DSLPCLKCFG_O_IGN (MOSC); 1=SYSCTL_DSLPCLKCFG_O_IO (PIOSC); 3=LFIOSC; 7=32.768 kHz
  [1] SYSCTL_DSLPCLKCFG_PIOSCPD — PIOSC Power Down Request
0x14C SYSCTL_SYSPROP ro — System Properties
  [0] SYSCTL_SYSPROP_FPU — FPU Present
0x150 SYSCTL_PIOSCCAL — Precision Internal Oscillator Calibration
  [31] SYSCTL_PIOSCCAL_UTEN — Use User Trim Value
  [9] SYSCTL_PIOSCCAL_CAL — Start Calibration
  [8] SYSCTL_PIOSCCAL_UPDATE — Update Trim
  [6:0] SYSCTL_PIOSCCAL_UT — User Trim Value
0x154 SYSCTL_PIOSCSTAT ro — Precision Internal Oscillator Statistics
  [22:16] SYSCTL_PIOSCSTAT_DT — Default Trim Value
  [9:8] SYSCTL_PIOSCSTAT_CR — Calibration Result
    0=SYSCTL_PIOSCSTAT_CRNONE (Calibration has not been attempted); 1=SYSCTL_PIOSCSTAT_CRPASS (The last calibration operation completed to meet 1% accuracy); 2=SYSCTL_PIOSCSTAT_CRFAIL (The last calibration operation failed to meet 1% accuracy)
  [6:0] SYSCTL_PIOSCSTAT_CT — Calibration Trim Value
0x160 SYSCTL_PLLFREQ0 — PLL Frequency 0
  [19:10] SYSCTL_PLLFREQ0_MFRAC — PLL M Fractional Value
  [9:0] SYSCTL_PLLFREQ0_MINT — PLL M Integer Value
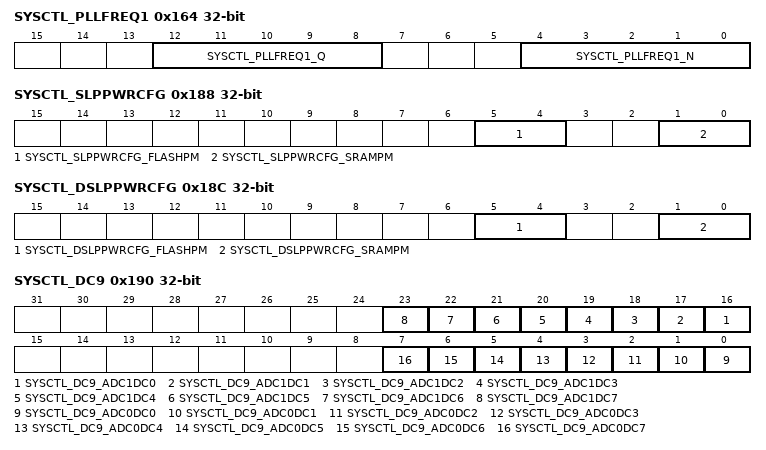
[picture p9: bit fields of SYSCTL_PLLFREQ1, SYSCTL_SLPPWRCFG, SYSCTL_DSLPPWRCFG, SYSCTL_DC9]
0x164 SYSCTL_PLLFREQ1 — PLL Frequency 1
  [12:8] SYSCTL_PLLFREQ1_Q — PLL Q Value
  [4:0] SYSCTL_PLLFREQ1_N — PLL N Value
0x168 SYSCTL_PLLSTAT ro — PLL Status
  [0] SYSCTL_PLLSTAT_LOCK — PLL Lock
0x188 SYSCTL_SLPPWRCFG — Sleep Power Configuration
  [5:4] SYSCTL_SLPPWRCFG_FLASHPM — Flash Power Modes
    0=SYSCTL_SLPPWRCFG_FLASHPM_NRM (Active Mode); 2=SYSCTL_SLPPWRCFG_FLASHPM_SLP (Low Power Mode)
  [1:0] SYSCTL_SLPPWRCFG_SRAMPM — SRAM Power Modes
    0=SYSCTL_SLPPWRCFG_SRAMPM_NRM (Active Mode); 1=SYSCTL_SLPPWRCFG_SRAMPM_SBY (Standby Mode); 3=SYSCTL_SLPPWRCFG_SRAMPM_LP (Low Power Mode)
0x18C SYSCTL_DSLPPWRCFG — Deep-Sleep Power Configuration
  [5:4] SYSCTL_DSLPPWRCFG_FLASHPM — Flash Power Modes
    0=SYSCTL_DSLPPWRCFG_FLASHPM_NRM (Active Mode); 2=SYSCTL_DSLPPWRCFG_FLASHPM_SLP (Low Power Mode)
  [1:0] SYSCTL_DSLPPWRCFG_SRAMPM — SRAM Power Modes
    0=SYSCTL_DSLPPWRCFG_SRAMPM_NRM (Active Mode); 1=SYSCTL_DSLPPWRCFG_SRAMPM_SBY (Standby Mode); 3=SYSCTL_DSLPPWRCFG_SRAMPM_LP (Low Power Mode)
0x190 SYSCTL_DC9 ro — Device Capabilities 9
  [n+16] SYSCTL_DC9_ADC1DC{n} (n=0..7) — ADC1 DC{n} Present
  [n] SYSCTL_DC9_ADC0DC{n} (n=0..7) — ADC0 DC{n} Present
0x1A0 SYSCTL_NVMSTAT ro — Non-Volatile Memory Information
  [0] SYSCTL_NVMSTAT_FWB — 32 Word Flash Write Buffer Available
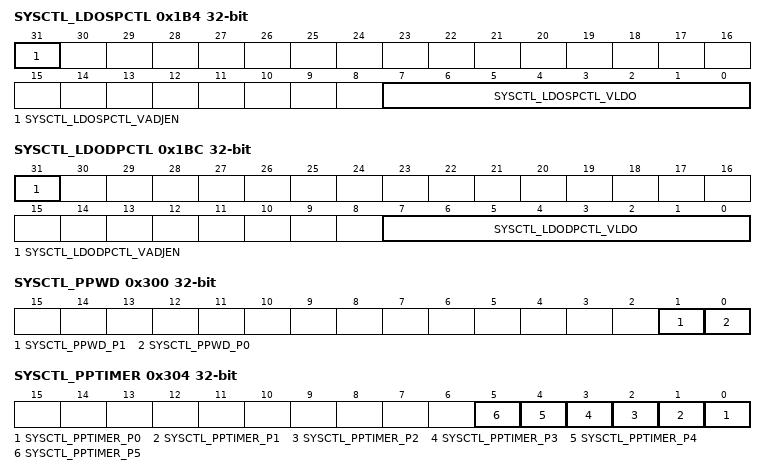
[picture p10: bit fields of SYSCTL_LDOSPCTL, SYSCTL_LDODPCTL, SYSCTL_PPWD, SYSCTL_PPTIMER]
0x1B4 SYSCTL_LDOSPCTL — LDO Sleep Power Control
  [31] SYSCTL_LDOSPCTL_VADJEN — Voltage Adjust Enable
  [7:0] SYSCTL_LDOSPCTL_VLDO — LDO Output Voltage
    18=SYSCTL_LDOSPCTL_VLDO_0_90V (0.90 V); 19=SYSCTL_LDOSPCTL_VLDO_0_95V (0.95 V); 20=SYSCTL_LDOSPCTL_VLDO_1_00V (1.00 V); 21=SYSCTL_LDOSPCTL_VLDO_1_05V (1.05 V); 22=SYSCTL_LDOSPCTL_VLDO_1_10V (1.10 V); 23=SYSCTL_LDOSPCTL_VLDO_1_15V (1.15 V); 24=SYSCTL_LDOSPCTL_VLDO_1_20V (1.20 V)
0x1BC SYSCTL_LDODPCTL — LDO Deep-Sleep Power Control
  [31] SYSCTL_LDODPCTL_VADJEN — Voltage Adjust Enable
  [7:0] SYSCTL_LDODPCTL_VLDO — LDO Output Voltage
    18=SYSCTL_LDODPCTL_VLDO_0_90V (0.90 V); 19=SYSCTL_LDODPCTL_VLDO_0_95V (0.95 V); 20=SYSCTL_LDODPCTL_VLDO_1_00V (1.00 V); 21=SYSCTL_LDODPCTL_VLDO_1_05V (1.05 V); 22=SYSCTL_LDODPCTL_VLDO_1_10V (1.10 V); 23=SYSCTL_LDODPCTL_VLDO_1_15V (1.15 V); 24=SYSCTL_LDODPCTL_VLDO_1_20V (1.20 V)
0x300 SYSCTL_PPWD ro — Watchdog Timer Peripheral Present
  [1] SYSCTL_PPWD_P1 — Watchdog Timer 1 Present
  [0] SYSCTL_PPWD_P0 — Watchdog Timer 0 Present
0x304 SYSCTL_PPTIMER ro — 16/32-Bit General-Purpose Timer Peripheral Present
  [n] SYSCTL_PPTIMER_P{n} (n=0..5) — 16/32-Bit General-Purpose Timer {n} Present
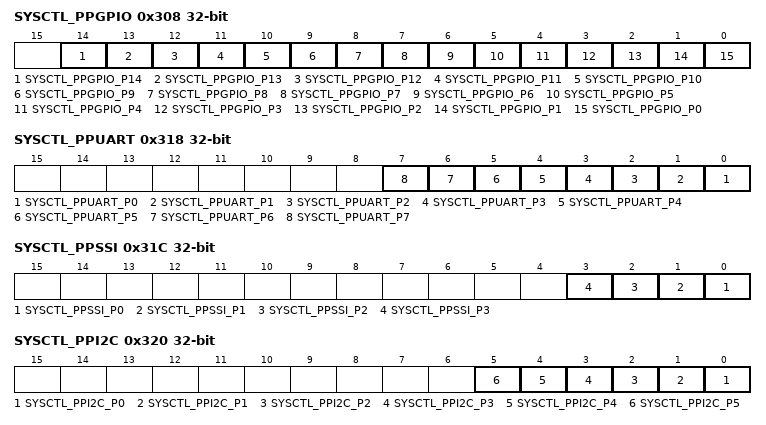
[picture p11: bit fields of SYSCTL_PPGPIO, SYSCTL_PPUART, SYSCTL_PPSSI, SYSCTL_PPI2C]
0x308 SYSCTL_PPGPIO ro — General-Purpose Input/Output Peripheral Present
  [14] SYSCTL_PPGPIO_P14 — GPIO Port Q Present
  [13] SYSCTL_PPGPIO_P13 — GPIO Port P Present
  [12] SYSCTL_PPGPIO_P12 — GPIO Port N Present
  [11] SYSCTL_PPGPIO_P11 — GPIO Port M Present
  [10] SYSCTL_PPGPIO_P10 — GPIO Port L Present
  [9] SYSCTL_PPGPIO_P9 — GPIO Port K Present
  [8] SYSCTL_PPGPIO_P8 — GPIO Port J Present
  [7] SYSCTL_PPGPIO_P7 — GPIO Port H Present
  [6] SYSCTL_PPGPIO_P6 — GPIO Port G Present
  [5] SYSCTL_PPGPIO_P5 — GPIO Port F Present
  [4] SYSCTL_PPGPIO_P4 — GPIO Port E Present
  [3] SYSCTL_PPGPIO_P3 — GPIO Port D Present
  [2] SYSCTL_PPGPIO_P2 — GPIO Port C Present
  [1] SYSCTL_PPGPIO_P1 — GPIO Port B Present
  [0] SYSCTL_PPGPIO_P0 — GPIO Port A Present
0x30C SYSCTL_PPDMA ro — Micro Direct Memory Access Peripheral Present
  [0] SYSCTL_PPDMA_P0 — uDMA Module Present
0x314 SYSCTL_PPHIB ro — Hibernation Peripheral Present
  [0] SYSCTL_PPHIB_P0 — Hibernation Module Present
0x318 SYSCTL_PPUART ro — Universal Asynchronous Receiver/Transmitter Peripheral Present
  [n] SYSCTL_PPUART_P{n} (n=0..7) — UART Module {n} Present
0x31C SYSCTL_PPSSI ro — Synchronous Serial Interface Peripheral Present
  [n] SYSCTL_PPSSI_P{n} (n=0..3) — SSI Module {n} Present
0x320 SYSCTL_PPI2C ro — Inter-Integrated Circuit Peripheral Present
  [n] SYSCTL_PPI2C_P{n} (n=0..5) — I2C Module {n} Present
0x328 SYSCTL_PPUSB ro — Universal Serial Bus Peripheral Present
  [0] SYSCTL_PPUSB_P0 — USB Module Present
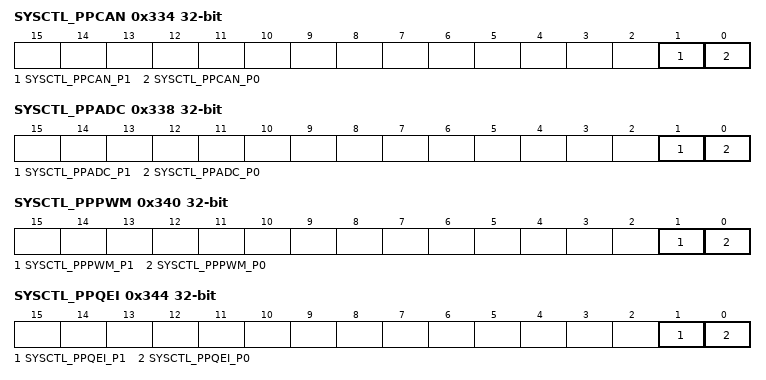
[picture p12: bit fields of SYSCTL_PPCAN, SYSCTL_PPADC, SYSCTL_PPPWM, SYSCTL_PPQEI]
0x334 SYSCTL_PPCAN ro — Controller Area Network Peripheral Present
  [1] SYSCTL_PPCAN_P1 — CAN Module 1 Present
  [0] SYSCTL_PPCAN_P0 — CAN Module 0 Present
0x338 SYSCTL_PPADC ro — Analog-to-Digital Converter Peripheral Present
  [1] SYSCTL_PPADC_P1 — ADC Module 1 Present
  [0] SYSCTL_PPADC_P0 — ADC Module 0 Present
0x33C SYSCTL_PPACMP ro — Analog Comparator Peripheral Present
  [0] SYSCTL_PPACMP_P0 — Analog Comparator Module Present
0x340 SYSCTL_PPPWM ro — Pulse Width Modulator Peripheral Present
  [1] SYSCTL_PPPWM_P1 — PWM Module 1 Present
  [0] SYSCTL_PPPWM_P0 — PWM Module 0 Present
0x344 SYSCTL_PPQEI ro — Quadrature Encoder Interface Peripheral Present
  [1] SYSCTL_PPQEI_P1 — QEI Module 1 Present
  [0] SYSCTL_PPQEI_P0 — QEI Module 0 Present
0x348 SYSCTL_PPLPC ro — Low Pin Count Interface Peripheral Present
  [0] SYSCTL_PPLPC_P0 — LPC Module Present
0x350 SYSCTL_PPPECI ro — Platform Environment Control Interface Peripheral Present
  [0] SYSCTL_PPPECI_P0 — PECI Module Present
0x354 SYSCTL_PPFAN ro — Fan Control Peripheral Present
  [0] SYSCTL_PPFAN_P0 — FAN Module 0 Present
0x358 SYSCTL_PPEEPROM ro — EEPROM Peripheral Present
  [0] SYSCTL_PPEEPROM_P0 — EEPROM Module Present
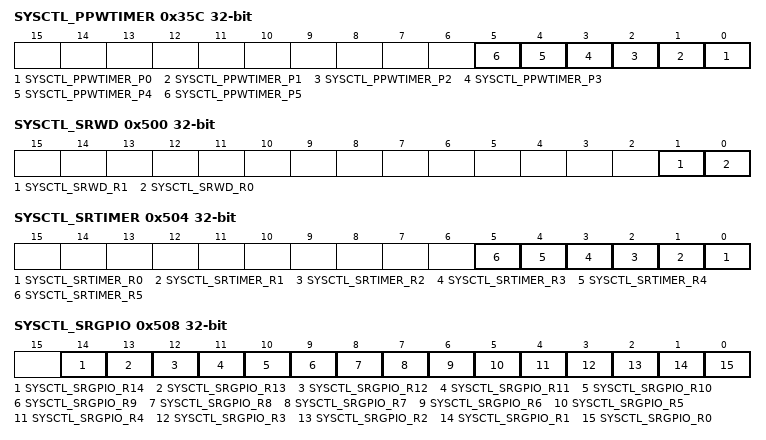
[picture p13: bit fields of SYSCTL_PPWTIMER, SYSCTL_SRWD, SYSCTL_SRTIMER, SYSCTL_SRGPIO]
0x35C SYSCTL_PPWTIMER ro — 32/64-Bit Wide General-Purpose Timer Peripheral Present
  [n] SYSCTL_PPWTIMER_P{n} (n=0..5) — 32/64-Bit Wide General-Purpose Timer {n} Present
0x500 SYSCTL_SRWD — Watchdog Timer Software Reset
  [1] SYSCTL_SRWD_R1 — Watchdog Timer 1 Software Reset
  [0] SYSCTL_SRWD_R0 — Watchdog Timer 0 Software Reset
0x504 SYSCTL_SRTIMER — 16/32-Bit General-Purpose Timer Software Reset
  [n] SYSCTL_SRTIMER_R{n} (n=0..5) — 16/32-Bit General-Purpose Timer {n} Software Reset
0x508 SYSCTL_SRGPIO — General-Purpose Input/Output Software Reset
  [14] SYSCTL_SRGPIO_R14 — GPIO Port Q Software Reset
  [13] SYSCTL_SRGPIO_R13 — GPIO Port P Software Reset
  [12] SYSCTL_SRGPIO_R12 — GPIO Port N Software Reset
  [11] SYSCTL_SRGPIO_R11 — GPIO Port M Software Reset
  [10] SYSCTL_SRGPIO_R10 — GPIO Port L Software Reset
  [9] SYSCTL_SRGPIO_R9 — GPIO Port K Software Reset
  [8] SYSCTL_SRGPIO_R8 — GPIO Port J Software Reset
  [7] SYSCTL_SRGPIO_R7 — GPIO Port H Software Reset
  [6] SYSCTL_SRGPIO_R6 — GPIO Port G Software Reset
  [5] SYSCTL_SRGPIO_R5 — GPIO Port F Software Reset
  [4] SYSCTL_SRGPIO_R4 — GPIO Port E Software Reset
  [3] SYSCTL_SRGPIO_R3 — GPIO Port D Software Reset
  [2] SYSCTL_SRGPIO_R2 — GPIO Port C Software Reset
  [1] SYSCTL_SRGPIO_R1 — GPIO Port B Software Reset
  [0] SYSCTL_SRGPIO_R0 — GPIO Port A Software Reset
0x50C SYSCTL_SRDMA — Micro Direct Memory Access Software Reset
  [0] SYSCTL_SRDMA_R0 — uDMA Module Software Reset
0x514 SYSCTL_SRHIB — Hibernation Software Reset
  [0] SYSCTL_SRHIB_R0 — Hibernation Module Software Reset
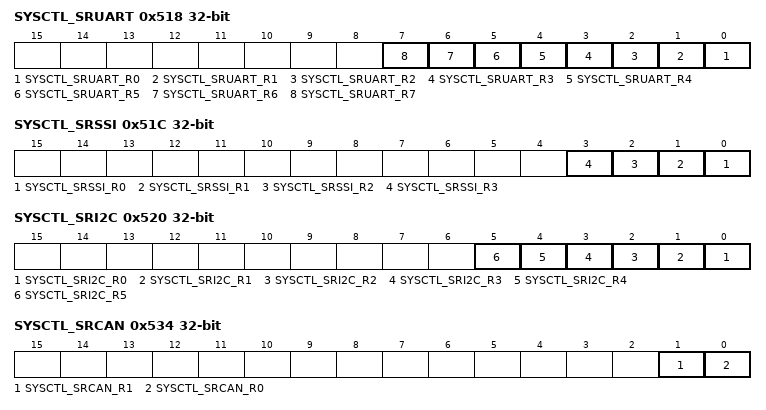
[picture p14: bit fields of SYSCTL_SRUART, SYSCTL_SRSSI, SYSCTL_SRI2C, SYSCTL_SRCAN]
0x518 SYSCTL_SRUART — Universal Asynchronous Receiver/Transmitter Software Reset
  [n] SYSCTL_SRUART_R{n} (n=0..7) — UART Module {n} Software Reset
0x51C SYSCTL_SRSSI — Synchronous Serial Interface Software Reset
  [n] SYSCTL_SRSSI_R{n} (n=0..3) — SSI Module {n} Software Reset
0x520 SYSCTL_SRI2C — Inter-Integrated Circuit Software Reset
  [n] SYSCTL_SRI2C_R{n} (n=0..5) — I2C Module {n} Software Reset
0x528 SYSCTL_SRUSB — Universal Serial Bus Software Reset
  [0] SYSCTL_SRUSB_R0 — USB Module Software Reset
0x534 SYSCTL_SRCAN — Controller Area Network Software Reset
  [1] SYSCTL_SRCAN_R1 — CAN Module 1 Software Reset
  [0] SYSCTL_SRCAN_R0 — CAN Module 0 Software Reset
0x538 SYSCTL_SRADC — Analog-to-Digital Converter Software Reset
  [1] SYSCTL_SRADC_R1 — ADC Module 1 Software Reset
  [0] SYSCTL_SRADC_R0 — ADC Module 0 Software Reset
0x53C SYSCTL_SRACMP — Analog Comparator Software Reset
  [0] SYSCTL_SRACMP_R0 — Analog Comparator Module 0 Software Reset
0x540 SYSCTL_SRPWM — Pulse Width Modulator Software Reset
  [1] SYSCTL_SRPWM_R1 — PWM Module 1 Software Reset
  [0] SYSCTL_SRPWM_R0 — PWM Module 0 Software Reset
0x544 SYSCTL_SRQEI — Quadrature Encoder Interface Software Reset
  [1] SYSCTL_SRQEI_R1 — QEI Module 1 Software Reset
  [0] SYSCTL_SRQEI_R0 — QEI Module 0 Software Reset
0x548 SYSCTL_SRLPC — Low Pin Count Interface Software Reset
  [0] SYSCTL_SRLPC_R0 — LPC Module Software Reset
0x550 SYSCTL_SRPECI — Platform Environment Control Interface Software Reset
  [0] SYSCTL_SRPECI_R0 — PECI Module Software Reset
0x554 SYSCTL_SRFAN — Fan Software Reset
  [0] SYSCTL_SRFAN_R0 — FAN 0 Module Software Reset
0x558 SYSCTL_SREEPROM — EEPROM Software Reset
  [0] SYSCTL_SREEPROM_R0 — EEPROM Module Software Reset
0x55C SYSCTL_SRWTIMER — 32/64-Bit Wide General-Purpose Timer Software Reset
  [n] SYSCTL_SRWTIMER_R{n} (n=0..5) — 32/64-Bit Wide General-Purpose Timer {n} Software Reset
0x600 SYSCTL_RCGCWD — Watchdog Timer Run Mode Clock Gating Control
  [1] SYSCTL_RCGCWD_R1 — Watchdog Timer 1 Run Mode Clock Gating Control
  [0] SYSCTL_RCGCWD_R0 — Watchdog Timer 0 Run Mode Clock Gating Control
0x604 SYSCTL_RCGCTIMER — 16/32-Bit General-Purpose Timer Run Mode Clock Gating Control
  [n] SYSCTL_RCGCTIMER_R{n} (n=0..5) — 16/32-Bit General-Purpose Timer {n} Run Mode Clock Gating Control
0x608 SYSCTL_RCGCGPIO — General-Purpose Input/Output Run Mode Clock Gating Control
  [14] SYSCTL_RCGCGPIO_R14 — GPIO Port Q Run Mode Clock Gating Control
  [13] SYSCTL_RCGCGPIO_R13 — GPIO Port P Run Mode Clock Gating Control
  [12] SYSCTL_RCGCGPIO_R12 — GPIO Port N Run Mode Clock Gating Control
  [11] SYSCTL_RCGCGPIO_R11 — GPIO Port M Run Mode Clock Gating Control
  [10] SYSCTL_RCGCGPIO_R10 — GPIO Port L Run Mode Clock Gating Control
  [9] SYSCTL_RCGCGPIO_R9 — GPIO Port K Run Mode Clock Gating Control
  [8] SYSCTL_RCGCGPIO_R8 — GPIO Port J Run Mode Clock Gating Control
  [7] SYSCTL_RCGCGPIO_R7 — GPIO Port H Run Mode Clock Gating Control
  [6] SYSCTL_RCGCGPIO_R6 — GPIO Port G Run Mode Clock Gating Control
  [5] SYSCTL_RCGCGPIO_R5 — GPIO Port F Run Mode Clock Gating Control
  [4] SYSCTL_RCGCGPIO_R4 — GPIO Port E Run Mode Clock Gating Control
  [3] SYSCTL_RCGCGPIO_R3 — GPIO Port D Run Mode Clock Gating Control
  [2] SYSCTL_RCGCGPIO_R2 — GPIO Port C Run Mode Clock Gating Control
  [1] SYSCTL_RCGCGPIO_R1 — GPIO Port B Run Mode Clock Gating Control
  [0] SYSCTL_RCGCGPIO_R0 — GPIO Port A Run Mode Clock Gating Control
0x60C SYSCTL_RCGCDMA — Micro Direct Memory Access Run Mode Clock Gating Control
  [0] SYSCTL_RCGCDMA_R0 — uDMA Module Run Mode Clock Gating Control
0x614 SYSCTL_RCGCHIB — Hibernation Run Mode Clock Gating Control
  [0] SYSCTL_RCGCHIB_R0 — Hibernation Module Run Mode Clock Gating Control
0x618 SYSCTL_RCGCUART — Universal Asynchronous Receiver/Transmitter Run Mode Clock Gating Control
  [n] SYSCTL_RCGCUART_R{n} (n=0..7) — UART Module {n} Run Mode Clock Gating Control
0x61C SYSCTL_RCGCSSI — Synchronous Serial Interface Run Mode Clock Gating Control
  [n] SYSCTL_RCGCSSI_R{n} (n=0..3) — SSI Module {n} Run Mode Clock Gating Control
0x620 SYSCTL_RCGCI2C — Inter-Integrated Circuit Run Mode Clock Gating Control
  [n] SYSCTL_RCGCI2C_R{n} (n=0..5) — I2C Module {n} Run Mode Clock Gating Control
0x628 SYSCTL_RCGCUSB — Universal Serial Bus Run Mode Clock Gating Control
  [0] SYSCTL_RCGCUSB_R0 — USB Module Run Mode Clock Gating Control
0x634 SYSCTL_RCGCCAN — Controller Area Network Run Mode Clock Gating Control
  [1] SYSCTL_RCGCCAN_R1 — CAN Module 1 Run Mode Clock Gating Control
  [0] SYSCTL_RCGCCAN_R0 — CAN Module 0 Run Mode Clock Gating Control
0x638 SYSCTL_RCGCADC — Analog-to-Digital Converter Run Mode Clock Gating Control
  [1] SYSCTL_RCGCADC_R1 — ADC Module 1 Run Mode Clock Gating Control
  [0] SYSCTL_RCGCADC_R0 — ADC Module 0 Run Mode Clock Gating Control
0x63C SYSCTL_RCGCACMP — Analog Comparator Run Mode Clock Gating Control
  [0] SYSCTL_RCGCACMP_R0 — Analog Comparator Module 0 Run Mode Clock Gating Control
0x640 SYSCTL_RCGCPWM — Pulse Width Modulator Run Mode Clock Gating Control
  [1] SYSCTL_RCGCPWM_R1 — PWM Module 1 Run Mode Clock Gating Control
  [0] SYSCTL_RCGCPWM_R0 — PWM Module 0 Run Mode Clock Gating Control
0x644 SYSCTL_RCGCQEI — Quadrature Encoder Interface Run Mode Clock Gating Control
  [1] SYSCTL_RCGCQEI_R1 — QEI Module 1 Run Mode Clock Gating Control
  [0] SYSCTL_RCGCQEI_R0 — QEI Module 0 Run Mode Clock Gating Control
0x648 SYSCTL_RCGCLPC — Low Pin Count Interface Run Mode Clock Gating Control
  [0] SYSCTL_RCGCLPC_R0 — LPC Module Run Mode Clock Gating Control
0x650 SYSCTL_RCGCPECI — Platform Environment Control Interface Run Mode Clock Gating Control
  [0] SYSCTL_RCGCPECI_R0 — PECI Module Run Mode Clock Gating Control
0x654 SYSCTL_RCGCFAN — Fan Run Mode Clock Gating Control
  [0] SYSCTL_RCGCFAN_R0 — FAN Module 0 Run Mode Clock Gating Control
0x658 SYSCTL_RCGCEEPROM — EEPROM Run Mode Clock Gating Control
  [0] SYSCTL_RCGCEEPROM_R0 — EEPROM Module Run Mode Clock Gating Control
0x65C SYSCTL_RCGCWTIMER — 32/64-Bit Wide General-Purpose Timer Run Mode Clock Gating Control
  [n] SYSCTL_RCGCWTIMER_R{n} (n=0..5) — 32/64-Bit Wide General-Purpose Timer {n} Run Mode Clock Gating Control
0x700 SYSCTL_SCGCWD — Watchdog Timer Sleep Mode Clock Gating Control
  [1] SYSCTL_SCGCWD_S1 — Watchdog Timer 1 Sleep Mode Clock Gating Control
  [0] SYSCTL_SCGCWD_S0 — Watchdog Timer 0 Sleep Mode Clock Gating Control
0x704 SYSCTL_SCGCTIMER — 16/32-Bit General-Purpose Timer Sleep Mode Clock Gating Control
  [n] SYSCTL_SCGCTIMER_S{n} (n=0..5) — 16/32-Bit General-Purpose Timer {n} Sleep Mode Clock Gating Control
0x708 SYSCTL_SCGCGPIO — General-Purpose Input/Output Sleep Mode Clock Gating Control
  [14] SYSCTL_SCGCGPIO_S14 — GPIO Port Q Sleep Mode Clock Gating Control
  [13] SYSCTL_SCGCGPIO_S13 — GPIO Port P Sleep Mode Clock Gating Control
  [12] SYSCTL_SCGCGPIO_S12 — GPIO Port N Sleep Mode Clock Gating Control
  [11] SYSCTL_SCGCGPIO_S11 — GPIO Port M Sleep Mode Clock Gating Control
  [10] SYSCTL_SCGCGPIO_S10 — GPIO Port L Sleep Mode Clock Gating Control
  [9] SYSCTL_SCGCGPIO_S9 — GPIO Port K Sleep Mode Clock Gating Control
  [8] SYSCTL_SCGCGPIO_S8 — GPIO Port J Sleep Mode Clock Gating Control
  [7] SYSCTL_SCGCGPIO_S7 — GPIO Port H Sleep Mode Clock Gating Control
  [6] SYSCTL_SCGCGPIO_S6 — GPIO Port G Sleep Mode Clock Gating Control
  [5] SYSCTL_SCGCGPIO_S5 — GPIO Port F Sleep Mode Clock Gating Control
  [4] SYSCTL_SCGCGPIO_S4 — GPIO Port E Sleep Mode Clock Gating Control
  [3] SYSCTL_SCGCGPIO_S3 — GPIO Port D Sleep Mode Clock Gating Control
  [2] SYSCTL_SCGCGPIO_S2 — GPIO Port C Sleep Mode Clock Gating Control
  [1] SYSCTL_SCGCGPIO_S1 — GPIO Port B Sleep Mode Clock Gating Control
  [0] SYSCTL_SCGCGPIO_S0 — GPIO Port A Sleep Mode Clock Gating Control
0x70C SYSCTL_SCGCDMA — Micro Direct Memory Access Sleep Mode Clock Gating Control
  [0] SYSCTL_SCGCDMA_S0 — uDMA Module Sleep Mode Clock Gating Control
0x714 SYSCTL_SCGCHIB — Hibernation Sleep Mode Clock Gating Control
  [0] SYSCTL_SCGCHIB_S0 — Hibernation Module Sleep Mode Clock Gating Control
0x718 SYSCTL_SCGCUART — Universal Asynchronous Receiver/Transmitter Sleep Mode Clock Gating Control
  [n] SYSCTL_SCGCUART_S{n} (n=0..7) — UART Module {n} Sleep Mode Clock Gating Control
0x71C SYSCTL_SCGCSSI — Synchronous Serial Interface Sleep Mode Clock Gating Control
  [n] SYSCTL_SCGCSSI_S{n} (n=0..3) — SSI Module {n} Sleep Mode Clock Gating Control
0x720 SYSCTL_SCGCI2C — Inter-Integrated Circuit Sleep Mode Clock Gating Control
  [n] SYSCTL_SCGCI2C_S{n} (n=0..5) — I2C Module {n} Sleep Mode Clock Gating Control
0x728 SYSCTL_SCGCUSB — Universal Serial Bus Sleep Mode Clock Gating Control
  [0] SYSCTL_SCGCUSB_S0 — USB Module Sleep Mode Clock Gating Control
0x734 SYSCTL_SCGCCAN — Controller Area Network Sleep Mode Clock Gating Control
  [1] SYSCTL_SCGCCAN_S1 — CAN Module 1 Sleep Mode Clock Gating Control
  [0] SYSCTL_SCGCCAN_S0 — CAN Module 0 Sleep Mode Clock Gating Control
0x738 SYSCTL_SCGCADC — Analog-to-Digital Converter Sleep Mode Clock Gating Control
  [1] SYSCTL_SCGCADC_S1 — ADC Module 1 Sleep Mode Clock Gating Control
  [0] SYSCTL_SCGCADC_S0 — ADC Module 0 Sleep Mode Clock Gating Control
0x73C SYSCTL_SCGCACMP — Analog Comparator Sleep Mode Clock Gating Control
  [0] SYSCTL_SCGCACMP_S0 — Analog Comparator Module 0 Sleep Mode Clock Gating Control
0x740 SYSCTL_SCGCPWM — Pulse Width Modulator Sleep Mode Clock Gating Control
  [1] SYSCTL_SCGCPWM_S1 — PWM Module 1 Sleep Mode Clock Gating Control
  [0] SYSCTL_SCGCPWM_S0 — PWM Module 0 Sleep Mode Clock Gating Control
0x744 SYSCTL_SCGCQEI — Quadrature Encoder Interface Sleep Mode Clock Gating Control
  [1] SYSCTL_SCGCQEI_S1 — QEI Module 1 Sleep Mode Clock Gating Control
  [0] SYSCTL_SCGCQEI_S0 — QEI Module 0 Sleep Mode Clock Gating Control
0x748 SYSCTL_SCGCLPC — Low Pin Count Interface Sleep Mode Clock Gating Control
  [0] SYSCTL_SCGCLPC_S0 — LPC Module Sleep Mode Clock Gating Control
0x750 SYSCTL_SCGCPECI — Platform Environment Control Interface Sleep Mode Clock Gating Control
  [0] SYSCTL_SCGCPECI_S0 — PECI Module Sleep Mode Clock Gating Control
0x754 SYSCTL_SCGCFAN — Fan Sleep Mode Clock Gating Control
  [0] SYSCTL_SCGCFAN_S0 — FAN Module Sleep Mode Clock Gating Control
0x758 SYSCTL_SCGCEEPROM — EEPROM Sleep Mode Clock Gating Control
  [0] SYSCTL_SCGCEEPROM_S0 — EEPROM Module Sleep Mode Clock Gating Control
0x75C SYSCTL_SCGCWTIMER — 32/64-Bit Wide General-Purpose Timer Sleep Mode Clock Gating Control
  [n] SYSCTL_SCGCWTIMER_S{n} (n=0..5) — 32/64-Bit Wide General-Purpose Timer {n} Sleep Mode Clock Gating Control
0x800 SYSCTL_DCGCWD — Watchdog Timer Deep-Sleep Mode Clock Gating Control
  [1] SYSCTL_DCGCWD_D1 — Watchdog Timer 1 Deep-Sleep Mode Clock Gating Control
  [0] SYSCTL_DCGCWD_D0 — Watchdog Timer 0 Deep-Sleep Mode Clock Gating Control
0x804 SYSCTL_DCGCTIMER — 16/32-Bit General-Purpose Timer Deep-Sleep Mode Clock Gating Control
  [n] SYSCTL_DCGCTIMER_D{n} (n=0..5) — 16/32-Bit General-Purpose Timer {n} Deep-Sleep Mode Clock Gating Control
0x808 SYSCTL_DCGCGPIO — General-Purpose Input/Output Deep-Sleep Mode Clock Gating Control
  [14] SYSCTL_DCGCGPIO_D14 — GPIO Port Q Deep-Sleep Mode Clock Gating Control
  [13] SYSCTL_DCGCGPIO_D13 — GPIO Port P Deep-Sleep Mode Clock Gating Control
  [12] SYSCTL_DCGCGPIO_D12 — GPIO Port N Deep-Sleep Mode Clock Gating Control
  [11] SYSCTL_DCGCGPIO_D11 — GPIO Port M Deep-Sleep Mode Clock Gating Control
  [10] SYSCTL_DCGCGPIO_D10 — GPIO Port L Deep-Sleep Mode Clock Gating Control
  [9] SYSCTL_DCGCGPIO_D9 — GPIO Port K Deep-Sleep Mode Clock Gating Control
  [8] SYSCTL_DCGCGPIO_D8 — GPIO Port J Deep-Sleep Mode Clock Gating Control
  [7] SYSCTL_DCGCGPIO_D7 — GPIO Port H Deep-Sleep Mode Clock Gating Control
  [6] SYSCTL_DCGCGPIO_D6 — GPIO Port G Deep-Sleep Mode Clock Gating Control
  [5] SYSCTL_DCGCGPIO_D5 — GPIO Port F Deep-Sleep Mode Clock Gating Control
  [4] SYSCTL_DCGCGPIO_D4 — GPIO Port E Deep-Sleep Mode Clock Gating Control
  [3] SYSCTL_DCGCGPIO_D3 — GPIO Port D Deep-Sleep Mode Clock Gating Control
  [2] SYSCTL_DCGCGPIO_D2 — GPIO Port C Deep-Sleep Mode Clock Gating Control
  [1] SYSCTL_DCGCGPIO_D1 — GPIO Port B Deep-Sleep Mode Clock Gating Control
  [0] SYSCTL_DCGCGPIO_D0 — GPIO Port A Deep-Sleep Mode Clock Gating Control
0x80C SYSCTL_DCGCDMA — Micro Direct Memory Access Deep-Sleep Mode Clock Gating Control
  [0] SYSCTL_DCGCDMA_D0 — uDMA Module Deep-Sleep Mode Clock Gating Control
0x814 SYSCTL_DCGCHIB — Hibernation Deep-Sleep Mode Clock Gating Control
  [0] SYSCTL_DCGCHIB_D0 — Hibernation Module Deep-Sleep Mode Clock Gating Control
0x818 SYSCTL_DCGCUART — Universal Asynchronous Receiver/Transmitter Deep-Sleep Mode Clock Gating Control
  [n] SYSCTL_DCGCUART_D{n} (n=0..7) — UART Module {n} Deep-Sleep Mode Clock Gating Control
0x81C SYSCTL_DCGCSSI — Synchronous Serial Interface Deep-Sleep Mode Clock Gating Control
  [n] SYSCTL_DCGCSSI_D{n} (n=0..3) — SSI Module {n} Deep-Sleep Mode Clock Gating Control
0x820 SYSCTL_DCGCI2C — Inter-Integrated Circuit Deep-Sleep Mode Clock Gating Control
  [n] SYSCTL_DCGCI2C_D{n} (n=0..5) — I2C Module {n} Deep-Sleep Mode Clock Gating Control
0x828 SYSCTL_DCGCUSB — Universal Serial Bus Deep-Sleep Mode Clock Gating Control
  [0] SYSCTL_DCGCUSB_D0 — USB Module Deep-Sleep Mode Clock Gating Control
0x834 SYSCTL_DCGCCAN — Controller Area Network Deep-Sleep Mode Clock Gating Control
  [1] SYSCTL_DCGCCAN_D1 — CAN Module 1 Deep-Sleep Mode Clock Gating Control
  [0] SYSCTL_DCGCCAN_D0 — CAN Module 0 Deep-Sleep Mode Clock Gating Control
0x838 SYSCTL_DCGCADC — Analog-to-Digital Converter Deep-Sleep Mode Clock Gating Control
  [1] SYSCTL_DCGCADC_D1 — ADC Module 1 Deep-Sleep Mode Clock Gating Control
  [0] SYSCTL_DCGCADC_D0 — ADC Module 0 Deep-Sleep Mode Clock Gating Control
0x83C SYSCTL_DCGCACMP — Analog Comparator Deep-Sleep Mode Clock Gating Control
  [0] SYSCTL_DCGCACMP_D0 — Analog Comparator Module 0 Deep-Sleep Mode Clock Gating Control
0x840 SYSCTL_DCGCPWM — Pulse Width Modulator Deep-Sleep Mode Clock Gating Control
  [1] SYSCTL_DCGCPWM_D1 — PWM Module 1 Deep-Sleep Mode Clock Gating Control
  [0] SYSCTL_DCGCPWM_D0 — PWM Module 0 Deep-Sleep Mode Clock Gating Control
0x844 SYSCTL_DCGCQEI — Quadrature Encoder Interface Deep-Sleep Mode Clock Gating Control
  [1] SYSCTL_DCGCQEI_D1 — QEI Module 1 Deep-Sleep Mode Clock Gating Control
  [0] SYSCTL_DCGCQEI_D0 — QEI Module 0 Deep-Sleep Mode Clock Gating Control
0x848 SYSCTL_DCGCLPC — Low Pin Count Interface Deep-Sleep Mode Clock Gating Control
  [0] SYSCTL_DCGCLPC_D0 — LPC Module Deep-Sleep Mode Clock Gating Control
0x850 SYSCTL_DCGCPECI — Platform Environment Control Interface Deep-Sleep Mode Clock Gating Control
  [0] SYSCTL_DCGCPECI_D0 — PECI Module Deep-Sleep Mode Clock Gating Control
0x854 SYSCTL_DCGCFAN — Fan Deep-Sleep Mode Clock Gating Control
  [0] SYSCTL_DCGCFAN_D0 — FAN Module 0 Deep-Sleep Mode Clock Gating Control
0x858 SYSCTL_DCGCEEPROM — EEPROM Deep-Sleep Mode Clock Gating Control
  [0] SYSCTL_DCGCEEPROM_D0 — EEPROM Module Deep-Sleep Mode Clock Gating Control
0x85C SYSCTL_DCGCWTIMER — 32/64-Bit Wide General-Purpose Timer Deep-Sleep Mode Clock Gating Control
  [n] SYSCTL_DCGCWTIMER_D{n} (n=0..5) — 32/64-Bit Wide General-Purpose Timer {n} Deep-Sleep Mode Clock Gating Control
0xA00 SYSCTL_PRWD ro — Watchdog Timer Peripheral Ready
  [1] SYSCTL_PRWD_R1 — Watchdog Timer 1 Peripheral Ready
  [0] SYSCTL_PRWD_R0 — Watchdog Timer 0 Peripheral Ready
0xA04 SYSCTL_PRTIMER ro — 16/32-Bit General-Purpose Timer Peripheral Ready
  [n] SYSCTL_PRTIMER_R{n} (n=0..5) — 16/32-Bit General-Purpose Timer {n} Peripheral Ready
0xA08 SYSCTL_PRGPIO ro — General-Purpose Input/Output Peripheral Ready
  [14] SYSCTL_PRGPIO_R14 — GPIO Port Q Peripheral Ready
  [13] SYSCTL_PRGPIO_R13 — GPIO Port P Peripheral Ready
  [12] SYSCTL_PRGPIO_R12 — GPIO Port N Peripheral Ready
  [11] SYSCTL_PRGPIO_R11 — GPIO Port M Peripheral Ready
  [10] SYSCTL_PRGPIO_R10 — GPIO Port L Peripheral Ready
  [9] SYSCTL_PRGPIO_R9 — GPIO Port K Peripheral Ready
  [8] SYSCTL_PRGPIO_R8 — GPIO Port J Peripheral Ready
  [7] SYSCTL_PRGPIO_R7 — GPIO Port H Peripheral Ready
  [6] SYSCTL_PRGPIO_R6 — GPIO Port G Peripheral Ready
  [5] SYSCTL_PRGPIO_R5 — GPIO Port F Peripheral Ready
  [4] SYSCTL_PRGPIO_R4 — GPIO Port E Peripheral Ready
  [3] SYSCTL_PRGPIO_R3 — GPIO Port D Peripheral Ready
  [2] SYSCTL_PRGPIO_R2 — GPIO Port C Peripheral Ready
  [1] SYSCTL_PRGPIO_R1 — GPIO Port B Peripheral Ready
  [0] SYSCTL_PRGPIO_R0 — GPIO Port A Peripheral Ready
0xA0C SYSCTL_PRDMA ro — Micro Direct Memory Access Peripheral Ready
  [0] SYSCTL_PRDMA_R0 — uDMA Module Peripheral Ready
0xA14 SYSCTL_PRHIB ro — Hibernation Peripheral Ready
  [0] SYSCTL_PRHIB_R0 — Hibernation Module Peripheral Ready
0xA18 SYSCTL_PRUART ro — Universal Asynchronous Receiver/Transmitter Peripheral Ready
  [n] SYSCTL_PRUART_R{n} (n=0..7) — UART Module {n} Peripheral Ready
0xA1C SYSCTL_PRSSI ro — Synchronous Serial Interface Peripheral Ready
  [n] SYSCTL_PRSSI_R{n} (n=0..3) — SSI Module {n} Peripheral Ready
0xA20 SYSCTL_PRI2C ro — Inter-Integrated Circuit Peripheral Ready
  [n] SYSCTL_PRI2C_R{n} (n=0..5) — I2C Module {n} Peripheral Ready
0xA28 SYSCTL_PRUSB ro — Universal Serial Bus Peripheral Ready
  [0] SYSCTL_PRUSB_R0 — USB Module Peripheral Ready
0xA34 SYSCTL_PRCAN ro — Controller Area Network Peripheral Ready
  [1] SYSCTL_PRCAN_R1 — CAN Module 1 Peripheral Ready
  [0] SYSCTL_PRCAN_R0 — CAN Module 0 Peripheral Ready
0xA38 SYSCTL_PRADC ro — Analog-to-Digital Converter Peripheral Ready
  [1] SYSCTL_PRADC_R1 — ADC Module 1 Peripheral Ready
  [0] SYSCTL_PRADC_R0 — ADC Module 0 Peripheral Ready
0xA3C SYSCTL_PRACMP ro — Analog Comparator Peripheral Ready
  [0] SYSCTL_PRACMP_R0 — Analog Comparator Module 0 Peripheral Ready
0xA40 SYSCTL_PRPWM ro — Pulse Width Modulator Peripheral Ready
  [1] SYSCTL_PRPWM_R1 — PWM Module 1 Peripheral Ready
  [0] SYSCTL_PRPWM_R0 — PWM Module 0 Peripheral Ready
0xA44 SYSCTL_PRQEI ro — Quadrature Encoder Interface Peripheral Ready
  [1] SYSCTL_PRQEI_R1 — QEI Module 1 Peripheral Ready
  [0] SYSCTL_PRQEI_R0 — QEI Module 0 Peripheral Ready
0xA48 SYSCTL_PRLPC ro — Low Pin Count Interface Peripheral Ready
  [0] SYSCTL_PRLPC_R0 — LPC Module Peripheral Ready
0xA50 SYSCTL_PRPECI ro — Platform Environment Control Interface Peripheral Ready
  [0] SYSCTL_PRPECI_R0 — PECI Module Peripheral Ready
0xA54 SYSCTL_PRFAN ro — Fan Peripheral Ready
  [0] SYSCTL_PRFAN_R0 — FAN Module Peripheral Ready
0xA58 SYSCTL_PREEPROM ro — EEPROM Peripheral Ready
  [0] SYSCTL_PREEPROM_R0 — EEPROM Module Peripheral Ready
0xA5C SYSCTL_PRWTIMER ro — 32/64-Bit Wide General-Purpose Timer Peripheral Ready
  [n] SYSCTL_PRWTIMER_R{n} (n=0..5) — 32/64-Bit Wide General-Purpose Timer {n} Peripheral Ready
